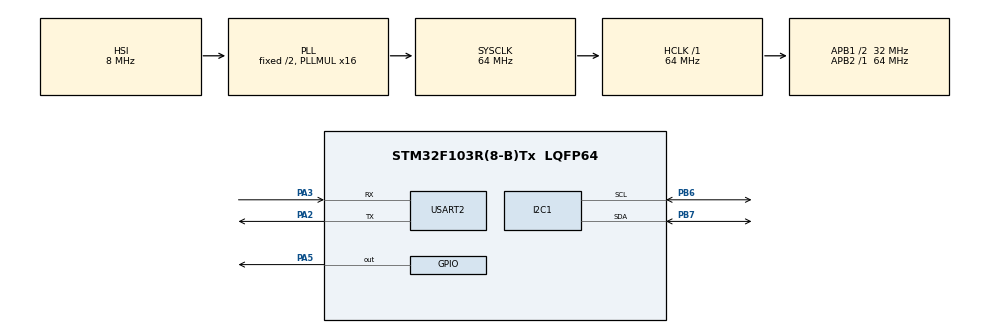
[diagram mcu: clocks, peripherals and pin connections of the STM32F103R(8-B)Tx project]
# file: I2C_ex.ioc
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Mcu.Family=STM32F1
Mcu.Name=STM32F103R(8-B)Tx
Mcu.Package=LQFP64
NVIC.PriorityGroup=NVIC_PRIORITYGROUP_4
NVIC.USART2_IRQn=true\:0\:0\:false\:false\:true\:true\:true\:true
PA2.Mode=Asynchronous
PA2.Signal=USART2_TX
PA3.Mode=Asynchronous
PA3.Signal=USART2_RX
PA5.Signal=GPIO_Output
PB6.Mode=I2C
PB6.Signal=I2C1_SCL
PB7.Mode=I2C
PB7.Signal=I2C1_SDA
ProjectManager.HeapSize=0x200
ProjectManager.StackSize=0x400
ProjectManager.TargetToolchain=CMake
RCC.AHBFreq_Value=64000000
RCC.APB1CLKDivider=RCC_HCLK_DIV2
RCC.APB1Freq_Value=32000000
RCC.APB1TimFreq_Value=64000000
RCC.APB2Freq_Value=64000000
RCC.APB2TimFreq_Value=64000000
RCC.HCLKFreq_Value=64000000
RCC.PLLMUL=RCC_PLL_MUL16
RCC.SYSCLKFreq_VALUE=64000000
RCC.SYSCLKSource=RCC_SYSCLKSOURCE_PLLCLK
RCC.USBFreq_Value=64000000
USART2.VirtualMode=VM_ASYNC
VP_SYS_VS_ND.Mode=No_Debug
board=custom

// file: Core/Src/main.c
/* USER CODE BEGIN Header */
/**
 ******************************************************************************
 * @file           : main.c
 * @brief          : Main program body
 ******************************************************************************
 * @attention
 *
 * Copyright (c) 2025 STMicroelectronics.
 * All rights reserved.
 *
 * This software is licensed under terms that can be found in the LICENSE file
 * in the root directory of this software component.
 * If no LICENSE file comes with this software, it is provided AS-IS.
 *
 ******************************************************************************
 */
/* USER CODE END Header */
#include "main.h"

/* USER CODE BEGIN Includes */
#include "lcd.h"
/* USER CODE END Includes */

I2C_HandleTypeDef hi2c1;

UART_HandleTypeDef huart2;

/* USER CODE BEGIN PV */
uint8_t success_msg[] = "SUCCESS\r\n";
uint8_t error_msg[] = "ERROR\r\n";
uint32_t address = 0x27;
int i = 0;
/* USER CODE END PV */

void SystemClock_Config(void);
static void MX_GPIO_Init(void);
static void MX_I2C1_Init(void);
static void MX_USART2_UART_Init(void);

int main(void) {

    /* MCU
     * Configuration--------------------------------------------------------*/

    /* Reset of all peripherals, Initializes the Flash interface and the
     * Systick. */
    HAL_Init();

    /* Configure the system clock */
    SystemClock_Config();

    /* Initialize all configured peripherals */
    MX_GPIO_Init();
    MX_I2C1_Init();
    MX_USART2_UART_Init();
    /* USER CODE BEGIN 2 */
    LCD_Init();
    HAL_UART_Transmit(&huart2, success_msg, 10, 0xFF);
    uint8_t str[2][17] = {"ABCD0123HelloWor", "ld!!!!!!!!! !!!!"};
    LCD_Write(str);
    /* USER CODE END 2 */

    /* Infinite loop */
    while (1) {

        /* USER CODE BEGIN 3 */
        // LCD_WriteChar(0x49);
    }
    /* USER CODE END 3 */
}

void SystemClock_Config(void) {
    RCC_OscInitTypeDef RCC_OscInitStruct = {0};
    RCC_ClkInitTypeDef RCC_ClkInitStruct = {0};

    /** Initializes the RCC Oscillators according to the specified parameters
     * in the RCC_OscInitTypeDef structure.
     */
    RCC_OscInitStruct.OscillatorType = RCC_OSCILLATORTYPE_HSI;
    RCC_OscInitStruct.HSIState = RCC_HSI_ON;
    RCC_OscInitStruct.HSICalibrationValue = RCC_HSICALIBRATION_DEFAULT;
    RCC_OscInitStruct.PLL.PLLState = RCC_PLL_ON;
    RCC_OscInitStruct.PLL.PLLSource = RCC_PLLSOURCE_HSI_DIV2;
    RCC_OscInitStruct.PLL.PLLMUL = RCC_PLL_MUL16;
    if (HAL_RCC_OscConfig(&RCC_OscInitStruct) != HAL_OK) {
        Error_Handler();
    }

    /** Initializes the CPU, AHB and APB buses clocks
     */
    RCC_ClkInitStruct.ClockType = RCC_CLOCKTYPE_HCLK | RCC_CLOCKTYPE_SYSCLK |
                                  RCC_CLOCKTYPE_PCLK1 | RCC_CLOCKTYPE_PCLK2;
    RCC_ClkInitStruct.SYSCLKSource = RCC_SYSCLKSOURCE_PLLCLK;
    RCC_ClkInitStruct.AHBCLKDivider = RCC_SYSCLK_DIV1;
    RCC_ClkInitStruct.APB1CLKDivider = RCC_HCLK_DIV2;
    RCC_ClkInitStruct.APB2CLKDivider = RCC_HCLK_DIV1;

    if (HAL_RCC_ClockConfig(&RCC_ClkInitStruct, FLASH_LATENCY_2) != HAL_OK) {
        Error_Handler();
    }
}

static void MX_I2C1_Init(void) {

    hi2c1.Instance = I2C1;
    hi2c1.Init.ClockSpeed = 100000;
    hi2c1.Init.DutyCycle = I2C_DUTYCYCLE_2;
    hi2c1.Init.OwnAddress1 = 0;
    hi2c1.Init.AddressingMode = I2C_ADDRESSINGMODE_7BIT;
    hi2c1.Init.DualAddressMode = I2C_DUALADDRESS_DISABLE;
    hi2c1.Init.OwnAddress2 = 0;
    hi2c1.Init.GeneralCallMode = I2C_GENERALCALL_DISABLE;
    hi2c1.Init.NoStretchMode = I2C_NOSTRETCH_DISABLE;
    if (HAL_I2C_Init(&hi2c1) != HAL_OK) {
        Error_Handler();
    }
}

static void MX_USART2_UART_Init(void) {

    huart2.Instance = USART2;
    huart2.Init.BaudRate = 115200;
    huart2.Init.WordLength = UART_WORDLENGTH_8B;
    huart2.Init.StopBits = UART_STOPBITS_1;
    huart2.Init.Parity = UART_PARITY_NONE;
    huart2.Init.Mode = UART_MODE_TX_RX;
    huart2.Init.HwFlowCtl = UART_HWCONTROL_NONE;
    huart2.Init.OverSampling = UART_OVERSAMPLING_16;
    if (HAL_UART_Init(&huart2) != HAL_OK) {
        Error_Handler();
    }
}

static void MX_GPIO_Init(void) {
    GPIO_InitTypeDef GPIO_InitStruct = {0};

    /* GPIO Ports Clock Enable */
    __HAL_RCC_GPIOA_CLK_ENABLE();
    __HAL_RCC_GPIOB_CLK_ENABLE();

    /*Configure GPIO pin Output Level */
    HAL_GPIO_WritePin(GPIOA, GPIO_PIN_5, GPIO_PIN_RESET);

    /*Configure GPIO pin : PA5 */
    GPIO_InitStruct.Pin = GPIO_PIN_5;
    GPIO_InitStruct.Mode = GPIO_MODE_OUTPUT_PP;
    GPIO_InitStruct.Pull = GPIO_NOPULL;
    GPIO_InitStruct.Speed = GPIO_SPEED_FREQ_LOW;
    HAL_GPIO_Init(GPIOA, &GPIO_InitStruct);

}

void Error_Handler(void) {
    /* USER CODE BEGIN Error_Handler_Debug */
    /* User can add his own implementation to report the HAL error return state
     */
    __disable_irq();
    while (1) {
    }
    /* USER CODE END Error_Handler_Debug */
}

#ifdef USE_FULL_ASSERT
/**
 * @brief  Reports the name of the source file and the source line number
 *         where the assert_param error has occurred.
 * @param  file: pointer to the source file name
 * @param  line: assert_param error line source number
 * @retval None
 */
void assert_failed(uint8_t *file, uint32_t line) {
    /* USER CODE BEGIN 6 */
    /* User can add his own implementation to report the file name and line
       number, ex: printf("Wrong parameters value: file %s on line %d\r\n",
       file, line) */
    /* USER CODE END 6 */
}
#endif /* USE_FULL_ASSERT */
